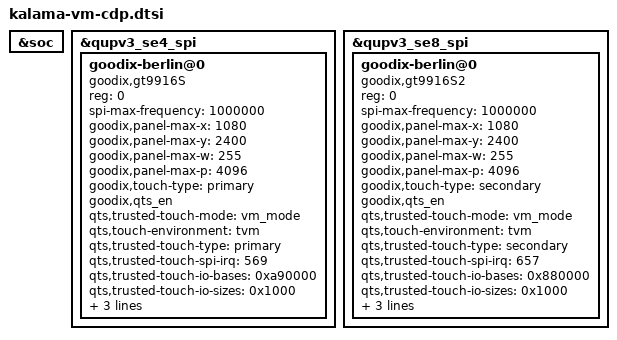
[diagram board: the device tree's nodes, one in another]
&soc {
};

&qupv3_se4_spi {
	status = "ok";
	goodix-berlin@0 {
		compatible = "goodix,gt9916S";
		reg = <0>;
		spi-max-frequency = <1000000>;
		goodix,panel-max-x = <1080>;
		goodix,panel-max-y = <2400>;
		goodix,panel-max-w = <255>;
		goodix,panel-max-p = <4096>;
		goodix,touch-type = "primary";
		goodix,qts_en;
		qts,trusted-touch-mode = "vm_mode";
		qts,touch-environment = "tvm";
		qts,trusted-touch-type = "primary";
		qts,trusted-touch-spi-irq = <569>;
		qts,trusted-touch-io-bases = <0xa90000>;
		qts,trusted-touch-io-sizes = <0x1000>;
		qts,trusted-touch-vm-gpio-list = <&tlmm 44 0 &tlmm 45 0 &tlmm 46 0
						&tlmm 47 0 &tlmm 24 0 &tlmm 25 0x2008>;
	};
};

&qupv3_se8_spi {
	status = "ok";
	goodix-berlin@0 {
		compatible = "goodix,gt9916S2";
		reg = <0>;
		spi-max-frequency = <1000000>;
		goodix,panel-max-x = <1080>;
		goodix,panel-max-y = <2400>;
		goodix,panel-max-w = <255>;
		goodix,panel-max-p = <4096>;
		goodix,touch-type = "secondary";
		goodix,qts_en;
		qts,trusted-touch-mode = "vm_mode";
		qts,touch-environment = "tvm";
		qts,trusted-touch-type = "secondary";
		qts,trusted-touch-spi-irq = <657>;
		qts,trusted-touch-io-bases = <0x880000>;
		qts,trusted-touch-io-sizes = <0x1000>;
		qts,trusted-touch-vm-gpio-list = <&tlmm 56 0 &tlmm 57 0 &tlmm 58 0
						&tlmm 59 0 &tlmm 13 0 &tlmm 48 0x2008>;
	};
};

